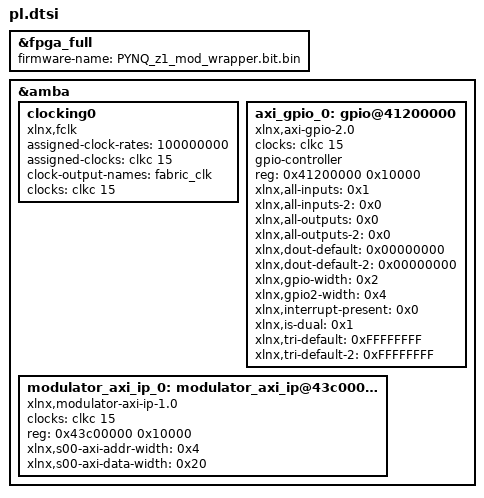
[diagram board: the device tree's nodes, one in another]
/*
 * CAUTION: This file is automatically generated by Xilinx.
 * Version:  
 * Today is: Fri Sep 24 10:40:26 2021
 */


/dts-v1/;
/plugin/;
/ {
	fragment@0 {
		target = <&fpga_full>;
		overlay0: __overlay__ {
			#address-cells = <1>;
			#size-cells = <1>;
			firmware-name = "PYNQ_z1_mod_wrapper.bit.bin";
		};
	};
	fragment@1 {
		target = <&amba>;
		overlay1: __overlay__ {
			clocking0: clocking0 {
				#clock-cells = <0>;
				assigned-clock-rates = <100000000>;
				assigned-clocks = <&clkc 15>;
				clock-output-names = "fabric_clk";
				clocks = <&clkc 15>;
				compatible = "xlnx,fclk";
			};
		};
	};
	fragment@2 {
		target = <&amba>;
		overlay2: __overlay__ {
			#address-cells = <1>;
			#size-cells = <1>;
			axi_gpio_0: gpio@41200000 {
				#gpio-cells = <3>;
				clock-names = "s_axi_aclk";
				clocks = <&clkc 15>;
				compatible = "xlnx,axi-gpio-2.0", "xlnx,xps-gpio-1.00.a";
				gpio-controller ;
				reg = <0x41200000 0x10000>;
				xlnx,all-inputs = <0x1>;
				xlnx,all-inputs-2 = <0x0>;
				xlnx,all-outputs = <0x0>;
				xlnx,all-outputs-2 = <0x0>;
				xlnx,dout-default = <0x00000000>;
				xlnx,dout-default-2 = <0x00000000>;
				xlnx,gpio-width = <0x2>;
				xlnx,gpio2-width = <0x4>;
				xlnx,interrupt-present = <0x0>;
				xlnx,is-dual = <0x1>;
				xlnx,tri-default = <0xFFFFFFFF>;
				xlnx,tri-default-2 = <0xFFFFFFFF>;
			};
			modulator_axi_ip_0: modulator_axi_ip@43c00000 {
				clock-names = "s00_axi_aclk";
				clocks = <&clkc 15>;
				compatible = "xlnx,modulator-axi-ip-1.0";
				reg = <0x43c00000 0x10000>;
				xlnx,s00-axi-addr-width = <0x4>;
				xlnx,s00-axi-data-width = <0x20>;
			};
		};
	};
};
